# GD32H75E register map
File version: 1.0
CPU: CM7 r1p2, little endian, MPU, FPU, 4 interrupt priority bits
Registers are 32-bit, read-write, reset 0x0 unless marked. A register's access mark holds for its fields unless they carry their own. Offsets are from the block's base; [hi:lo] are bit positions; {n}, {i} and the like mark numbered series.

## CMP — Comparator
Base 0x58003800
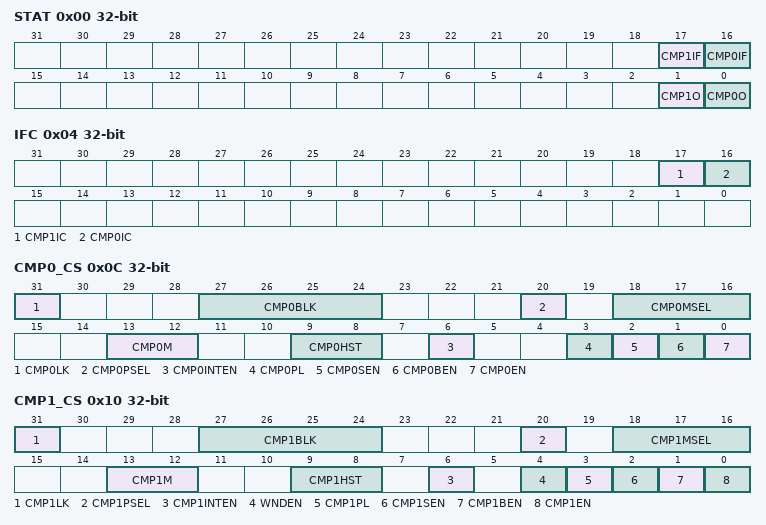
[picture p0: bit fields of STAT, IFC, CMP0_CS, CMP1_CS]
0x00 STAT access per field — Status register
  [17] CMP1IF rw — CMP1 interrupt flag
  [16] CMP0IF rw — CMP0 interrupt flag
  [1] CMP1O ro — CMP1 output
  [0] CMP0O ro — CMP0 output
0x04 IFC wo — Interrupt flag clear register
  [17] CMP1IC — CMP1 interrupt flag clear
  [16] CMP0IC — CMP0 interrupt flag clear
0x08 SR — Alternate select register
  [10:0] AFSE — CMP alternate function of output ports select
0x0C CMP0_CS — CMP0 Control/status register
  [31] CMP0LK — CMP0 lock
  [27:24] CMP0BLK — CMP0 output blanking source
  [20] CMP0PSEL — CMP0_IP input selection
  [18:16] CMP0MSEL — CMP0_IM internal input selection
  [13:12] CMP0M — CMP0 mode
  [9:8] CMP0HST — CMP0 hysteresis
  [6] CMP0INTEN — CMP0 interrupt enable
  [3] CMP0PL — Polarity of CMP0 output
  [2] CMP0SEN — Voltage scaler enable bit
  [1] CMP0BEN — Scaler bridge enable bit
  [0] CMP0EN — CMP0 enable
0x10 CMP1_CS — CMP1 Control/status register
  [31] CMP1LK — CMP1 lock
  [27:24] CMP1BLK — CMP1 output blanking source
  [20] CMP1PSEL — CMP1_IP input selection
  [18:16] CMP1MSEL — CMP1_IM internal input selection
  [13:12] CMP1M — CMP1 mode
  [9:8] CMP1HST — CMP1 hysteresis
  [6] CMP1INTEN — CMP1 interrupt enable
  [4] WNDEN — Window mode enable
  [3] CMP1PL — Polarity of CMP1 output
  [2] CMP1SEN — Voltage scaler enable bit
  [1] CMP1BEN — Scaler bridge enable bit
  [0] CMP1EN — CMP1 enable

## CRC — CRC calculation unit
Base 0x58024C00
0x00 DATA reset 0xFFFFFFFF
  [31:0] DATA — CRC calculation result bits
0x04 FDATA — Free data register
  [7:0] FDATA — Free data register bits
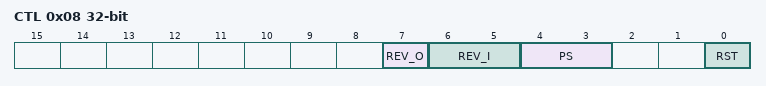
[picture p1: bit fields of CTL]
0x08 CTL — Control register
  [7] REV_O — Reverse output data value in bit order
  [6:5] REV_I — Reverse type for input date
  [4:3] PS — Size of polynomial
  [0] RST — Software writes and reads
0x10 IDATA reset 0xFFFFFFFF — Initialization data register
  [31:0] IDATA — Configurable initial CRC data value
0x14 POLY reset 0x4C11DB7 — Polynomial register
  [31:0] POLY — User configurable polynomial value

## CTC — Clock trim controller
Base 0x40008400
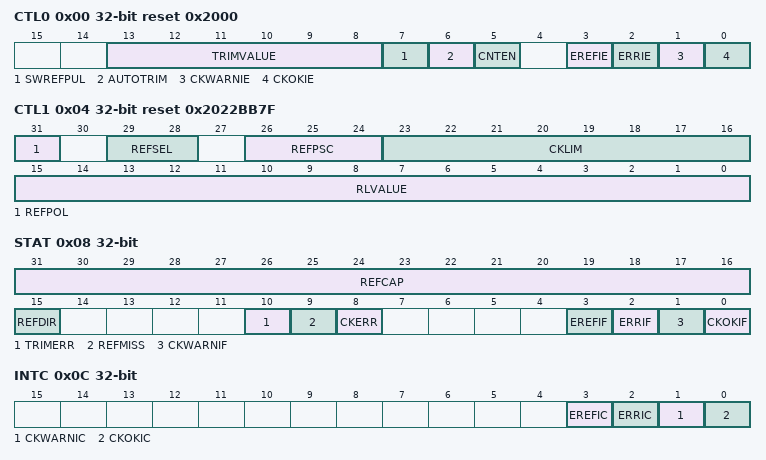
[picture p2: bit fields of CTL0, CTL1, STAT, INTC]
0x00 CTL0 access per field reset 0x2000 — Control register 0
  [13:8] TRIMVALUE rw — IRC48M trim value
  [7] SWREFPUL wo — Software reference source sync pulse
  [6] AUTOTRIM rw — Hardware automatically trim mode
  [5] CNTEN rw — CTC counter enable
  [3] EREFIE rw — EREFIF interrupt enable
  [2] ERRIE rw — Error (ERRIF) interrupt enable
  [1] CKWARNIE rw — Clock trim warning (CKWARNIF) interrupt enable
  [0] CKOKIE rw — Clock trim OK (CKOKIF) interrupt enable
0x04 CTL1 reset 0x2022BB7F — Control register 1
  [31] REFPOL — Reference signal source polarity
  [29:28] REFSEL — Reference signal source selection
  [26:24] REFPSC — Reference signal source prescaler
  [23:16] CKLIM — Clock trim base limit value
  [15:0] RLVALUE — CTC counter reload value
0x08 STAT ro — Status register
  [31:16] REFCAP — CTC counter capture when reference sync pulse
  [15] REFDIR — CTC trim counter direction when reference sync pulse
  [10] TRIMERR — Trim value error bit
  [9] REFMISS — Reference sync pulse miss
  [8] CKERR — Clock trim error bit
  [3] EREFIF — Expect reference interrupt flag
  [2] ERRIF — Error interrupt flag
  [1] CKWARNIF — Clock trim warning interrupt flag
  [0] CKOKIF — Clock trim OK interrupt flag
0x0C INTC wirte-only — Interrupt clear register
  [3] EREFIC — EREFIF interrupt clear bit
  [2] ERRIC — ERRIF interrupt clear bit
  [1] CKWARNIC — CKWARNIF interrupt clear bit
  [0] CKOKIC — CKOKIF interrupt clear bit

## DBG — Debug
Base 0xE00E1000
0x00 ID ro — ID code register
  [31:0] ID_CODE — DBG ID code register
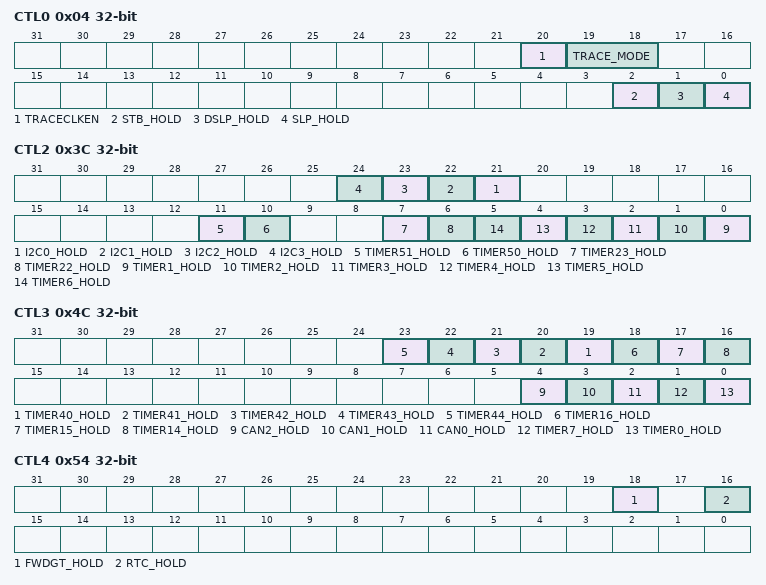
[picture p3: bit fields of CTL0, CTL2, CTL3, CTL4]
0x04 CTL0 — Control register0
  [20] TRACECLKEN — Trace port clock enable
  [19:18] TRACE_MODE — Trace pin allocation mode
  [2] STB_HOLD — Standby mode hold bit
  [1] DSLP_HOLD — Deep-sleep mode hold bit
  [0] SLP_HOLD — Sleep mode hold bit
0x34 CTL1 — Control register1
  [6] WWDGT_HOLD — WWDGT hold bit
0x3C CTL2 — Control register2
  [n+21] I2C{n}_HOLD (n=0..3) — I2C{n} hold bit
  [11] TIMER51_HOLD — TIMER51 hold bit
  [10] TIMER50_HOLD — TIMER50 hold bit
  [7] TIMER23_HOLD — TIMER23 hold bit
  [6] TIMER22_HOLD — TIMER22 hold bit
  [n-1] TIMER{n}_HOLD (n=1..6) — TIMER{n} hold bit
0x4C CTL3 — Control register3
  [n-21] TIMER{n}_HOLD (n=40..44) — TIMER{n} hold bit
  [18] TIMER16_HOLD — TIMER16 hold bit
  [17] TIMER15_HOLD — TIMER15 hold bit
  [16] TIMER14_HOLD — TIMER14 hold bit
  [4] CAN2_HOLD — CAN2 hold bit
  [3] CAN1_HOLD — CAN1 hold bit
  [2] CAN0_HOLD — CAN0 hold bit
  [1] TIMER7_HOLD — TIMER7 hold bit
  [0] TIMER0_HOLD — TIMER0 hold bit
0x54 CTL4 — Control register4
  [18] FWDGT_HOLD — FWDGT hold bit
  [16] RTC_HOLD — RTC hold bit
